AUTOSAR XML (schema 4-2-2)
package /ComponentTypes
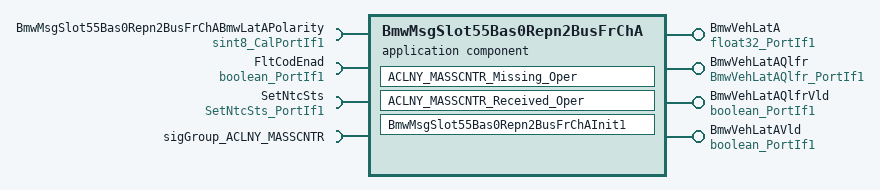
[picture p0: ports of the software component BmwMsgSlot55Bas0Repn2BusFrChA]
  application sw component type BmwMsgSlot55Bas0Repn2BusFrChA
    4 x provide port:
      BmwVehLatA: nonqueued-sender-com-spec{data-element=Val, init-value=0}, provided-interface=float32_PortIf1
      BmwVehLatAQlfr: nonqueued-sender-com-spec{data-element=Val, init-value=15}, provided-interface=BmwVehLatAQlfr_PortIf1
      BmwVehLatAQlfrVld: nonqueued-sender-com-spec{data-element=Logl, init-value=0}, provided-interface=boolean_PortIf1
      BmwVehLatAVld: nonqueued-sender-com-spec{data-element=Logl, init-value=0}, provided-interface=boolean_PortIf1
    4 x require port:
      BmwMsgSlot55Bas0Repn2BusFrChABmwLatAPolarity: parameter-require-com-spec{init-value=-1, parameter=Val}, required-interface=sint8_CalPortIf1
      FltCodEnad: nonqueued-receiver-com-spec{data-element=Logl, filter=data-filter-type=ALWAYS, init-value=1}, required-interface=boolean_PortIf1
      SetNtcSts: client-com-spec=Oper, required-interface=SetNtcSts_PortIf1
      sigGroup_ACLNY_MASSCNTR: nonqueued-receiver-com-spec{data-element=sigGroup_ACLNY_MASSCNTR, uses-end-to-end-protection=true, alive-timeout=0.015, enable-update=true, filter=data-filter-type=ALWAYS, init-value=fields=[ACLNY_MASSCNTR_dummy_12_15:0, ACLNY_COG:65535, QU_ACLNY_COG:15, ACLNY_COG_ERR_AMP:0, ALIV_ACLNY_COG:15, CRC_ACLNY_COG:0]}, required-interface=sigGroup_ACLNY_MASSCNTR
    behavior BmwMsgSlot55Bas0Repn2BusFrChA_InternalBehavior
      ar-typed-per-instance-memorys:
        12 x data, all with sw-calibration-access=READ-ONLY:
          AclnyCogFaildCnt: type=uint8
          AclnyCogPassdCnt: type=uint8
          AlvFaildCnt: type=uint8
          AlvPassdCnt: type=uint8
          BmwVehLatAPrev: type=float32
          BmwVehLatAQlfrPrev: type=BmwVehLatAQlfr1
          CrcFaildCnt: type=uint8
          CrcPassdCnt: type=uint8
          MissingMsgCnt: type=uint8
          QuAclnyCogFaildCnt: type=uint8
          QuAclnyCogPassdCnt: type=uint8
          RxdMsgCnt: type=uint8
      data receive error event DRET_ACLNY_MASSCNTR_Missing_Oper_sigGroup_ACLNY_MASSCNTR_sigGroup_ACLNY_MASSCNTR: start-on-event=ACLNY_MASSCNTR_Missing_Oper, data=sigGroup_ACLNY_MASSCNTR.sigGroup_ACLNY_MASSCNTR
      data received event DRT_ACLNY_MASSCNTR_Received_Oper_sigGroup_ACLNY_MASSCNTR_sigGroup_ACLNY_MASSCNTR: start-on-event=ACLNY_MASSCNTR_Received_Oper, data=sigGroup_ACLNY_MASSCNTR.sigGroup_ACLNY_MASSCNTR
      init event BmwMsgSlot55Bas0Repn2BusFrChA_InitEvent: start-on-event=BmwMsgSlot55Bas0Repn2BusFrChAInit1
      port-api-options:
        enable-take-address=false, error-handling=NO-TRANSFORMER-ERROR-HANDLING, indirect-api=false, port=BmwMsgSlot55Bas0Repn2BusFrChABmwLatAPolarity
        enable-take-address=false, error-handling=NO-TRANSFORMER-ERROR-HANDLING, indirect-api=false, port=BmwVehLatA
        enable-take-address=false, error-handling=NO-TRANSFORMER-ERROR-HANDLING, indirect-api=false, port=BmwVehLatAQlfr
        enable-take-address=false, error-handling=NO-TRANSFORMER-ERROR-HANDLING, indirect-api=false, port=BmwVehLatAQlfrVld
        enable-take-address=false, error-handling=NO-TRANSFORMER-ERROR-HANDLING, indirect-api=false, port=BmwVehLatAVld
        enable-take-address=false, error-handling=NO-TRANSFORMER-ERROR-HANDLING, indirect-api=false, port=FltCodEnad
        enable-take-address=false, error-handling=NO-TRANSFORMER-ERROR-HANDLING, indirect-api=false, port=SetNtcSts
        enable-take-address=false, error-handling=NO-TRANSFORMER-ERROR-HANDLING, indirect-api=false, port=sigGroup_ACLNY_MASSCNTR
      runnable ACLNY_MASSCNTR_Missing_Oper
        data-receive-point-by-arguments:
          access REC_FltCodEnad_Logl: accessed-variable=FltCodEnad.Logl
          access REC_sigGroup_ACLNY_MASSCNTR_sigGroup_ACLNY_MASSCNTR: accessed-variable=sigGroup_ACLNY_MASSCNTR.sigGroup_ACLNY_MASSCNTR
        data-send-points:
          4 x access:
            SEND_BmwLatA_Val: accessed-variable=BmwVehLatA.Val
            SEND_BmwLatAQlfr_Val: accessed-variable=BmwVehLatAQlfr.Val
            SEND_BmwLatAQlfrVld_Logl: accessed-variable=BmwVehLatAQlfrVld.Logl
            SEND_BmwLatAVld_Logl: accessed-variable=BmwVehLatAVld.Logl
        sync call SC_SetNtcSts_Oper: operation=SetNtcSts.Oper, timeout=0
      runnable ACLNY_MASSCNTR_Received_Oper
        data-receive-point-by-arguments:
          access REC_FltCodEnad_Logl: accessed-variable=FltCodEnad.Logl
          access REC_sigGroup_ACLNY_MASSCNTR_sigGroup_ACLNY_MASSCNTR: accessed-variable=sigGroup_ACLNY_MASSCNTR.sigGroup_ACLNY_MASSCNTR
        data-send-points:
          4 x access:
            SEND_BmwLatA_Val: accessed-variable=BmwVehLatA.Val
            SEND_BmwLatAQlfr_Val: accessed-variable=BmwVehLatAQlfr.Val
            SEND_BmwLatAQlfrVld_Logl: accessed-variable=BmwVehLatAQlfrVld.Logl
            SEND_BmwLatAVld_Logl: accessed-variable=BmwVehLatAVld.Logl
        sync call SC_SetNtcSts_Oper: operation=SetNtcSts.Oper, timeout=0
      runnable BmwMsgSlot55Bas0Repn2BusFrChAInit1
        data-receive-point-by-arguments:
          access REC_FltCodEnad_Logl: accessed-variable=FltCodEnad.Logl
          access REC_sigGroup_ACLNY_MASSCNTR_sigGroup_ACLNY_MASSCNTR: accessed-variable=sigGroup_ACLNY_MASSCNTR.sigGroup_ACLNY_MASSCNTR
        data-send-points:
          4 x access:
            SEND_BmwLatA_Val: accessed-variable=BmwVehLatA.Val
            SEND_BmwLatAQlfr_Val: accessed-variable=BmwVehLatAQlfr.Val
            SEND_BmwLatAQlfrVld_Logl: accessed-variable=BmwVehLatAQlfrVld.Logl
            SEND_BmwLatAVld_Logl: accessed-variable=BmwVehLatAVld.Logl
        sync call SC_SetNtcSts_Oper: operation=SetNtcSts.Oper, timeout=0
  swc implementation BmwMsgSlot55Bas0Repn2BusFrChA_Implementation: behavior=BmwMsgSlot55Bas0Repn2BusFrChA_InternalBehavior
    code-descriptors:
      code Default: artifact-descriptors=autosar-engineering-object={short-label=Default, category=SWSRC}
